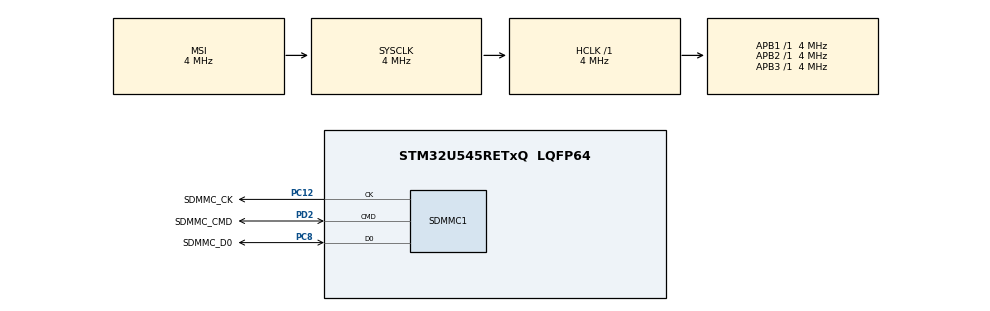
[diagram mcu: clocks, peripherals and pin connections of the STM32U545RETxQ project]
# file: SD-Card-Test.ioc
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CORTEX_M33_NS.userName=CORTEX_M33
Mcu.Family=STM32U5
Mcu.Name=STM32U545RETxQ
Mcu.Package=LQFP64
NVIC.PriorityGroup=NVIC_PRIORITYGROUP_4
PC12.GPIO_Label=SDMMC_CK
PC12.Mode=SD_1_bit
PC12.Signal=SDMMC1_CK
PC8.GPIO_Label=SDMMC_D0
PC8.GPIO_PuPd=GPIO_PULLUP
PC8.Mode=SD_1_bit
PC8.Signal=SDMMC1_D0
PD2.GPIO_Label=SDMMC_CMD
PD2.GPIO_PuPd=GPIO_PULLUP
PD2.Mode=SD_1_bit
PD2.Signal=SDMMC1_CMD
ProjectManager.HeapSize=0x200
ProjectManager.StackSize=0x400
ProjectManager.TargetToolchain=STM32CubeIDE
RCC.ADCFreq_Value=16000000
RCC.AHBFreq_Value=4000000
RCC.APB1Freq_Value=4000000
RCC.APB1TimFreq_Value=4000000
RCC.APB2Freq_Value=4000000
RCC.APB2TimFreq_Value=4000000
RCC.APB3Freq_Value=4000000
RCC.CortexFreq_Value=4000000
RCC.DACCLockSelectionVirtual=RCC_DAC1CLKSOURCE_LSI
RCC.DACCLockSelectionVirtualString=RCC_DAC1CLKSOURCE_LSI
RCC.EPOD_VALUE=4000000
RCC.HCLKFreq_Value=4000000
RCC.HSE_VALUE=16000000
RCC.HSI48_VALUE=48000000
RCC.HSI_VALUE=16000000
RCC.LSE_VALUE=32768
RCC.LSIDIV_VALUE=32000
RCC.MSI_VALUE=4000000
RCC.PLL2FRACN=0
RCC.PLL3FRACN=0
RCC.PLLFRACN=0
RCC.PWR_Regulator_Voltage_Scale=PWR_REGULATOR_VOLTAGE_SCALE3
RCC.SDMMCClockSelection=RCC_SDMMCCLKSOURCE_CLK48
RCC.SYSCLKFreq_VALUE=4000000
RCC.USBFreq_Value=48000000
RCC.VCOOutputFreq_Value=516000000
SDMMC1.ClockDiv=59
SDMMC1.HardwareFlowControl=SDMMC_HARDWARE_FLOW_CONTROL_DISABLE
VP_LPBAMQUEUE_VS_QUEUE.Mode=QUEUEMODE
VP_MEMORYMAP_VS_MEMORYMAP.Mode=CurAppReg
VP_PWR_VS_SECSignals.Mode=Security/Privilege
board=custom

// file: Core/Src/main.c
/* USER CODE BEGIN Header */
/**
  ******************************************************************************
  * @file           : main.c
  * @brief          : Main program body
  ******************************************************************************
  * @attention
  *
  * Copyright (c) 2025 STMicroelectronics.
  * All rights reserved.
  *
  * This software is licensed under terms that can be found in the LICENSE file
  * in the root directory of this software component.
  * If no LICENSE file comes with this software, it is provided AS-IS.
  *
  ******************************************************************************
  */
/* USER CODE END Header */
#include "main.h"

SD_HandleTypeDef hsd1;

/* USER CODE BEGIN PV */
char SDPath[4];
FATFS SDFatFs;
static uint8_t buffer[_MAX_SS];

/* USER CODE END PV */

void SystemClock_Config(void);
static void MX_GPIO_Init(void);
static void MX_SDMMC1_SD_Init(void);

int main(void)
{

  /* MCU Configuration--------------------------------------------------------*/

  /* Reset of all peripherals, Initializes the Flash interface and the Systick. */
  HAL_Init();

  /* USER CODE BEGIN Init */
  __HAL_RCC_PWR_CLK_ENABLE();

  /* USER CODE END Init */

  /* Configure the system clock */
  SystemClock_Config();

  /* Initialize all configured peripherals */
  MX_GPIO_Init();
  MX_SDMMC1_SD_Init();
  /* USER CODE BEGIN 2 */

  FRESULT fileResult;
  FATFS SDFatFs;

	BYTE bootSectorBuffer[512];

	DRESULT dataResult;

	UINT bytesWritten;

  // Link driver
  if (FATFS_LinkDriver(&SD_Driver, SDPath) == 0)
  {
		char label[12];
		DWORD serialNumber;
		fileResult = f_mount(&SDFatFs, SDPath, 1);
		if (fileResult != FR_OK)
		{
			Error_Handler();
		}

		FIL file;
		fileResult = f_open(&file, "0:hello69.txt", FA_WRITE | FA_CREATE_ALWAYS);
		if (fileResult != FR_OK)
		{
			Error_Handler();
		}

		const char* fileContents = "NO FUCKING WAY\n";
		fileResult = f_write(&file, fileContents, strlen(fileContents), &bytesWritten);
		if (fileResult != FR_OK || bytesWritten != strlen(fileContents))
		{
			Error_Handler();
		}

		f_close(&file);
		f_mount(NULL, "", 1);

  }

  /* USER CODE END 2 */

  /* Infinite loop */
  while (1)
  {

  }
}

void SystemClock_Config(void)
{
  RCC_OscInitTypeDef RCC_OscInitStruct = {0};
  RCC_ClkInitTypeDef RCC_ClkInitStruct = {0};

  /** Configure the main internal regulator output voltage
  */
  if (HAL_PWREx_ControlVoltageScaling(PWR_REGULATOR_VOLTAGE_SCALE3) != HAL_OK)
  {
    Error_Handler();
  }

  /** Initializes the CPU, AHB and APB buses clocks
  */
  RCC_OscInitStruct.OscillatorType = RCC_OSCILLATORTYPE_HSI48|RCC_OSCILLATORTYPE_MSI;
  RCC_OscInitStruct.HSI48State = RCC_HSI48_ON;
  RCC_OscInitStruct.MSIState = RCC_MSI_ON;
  RCC_OscInitStruct.MSICalibrationValue = RCC_MSICALIBRATION_DEFAULT;
  RCC_OscInitStruct.MSIClockRange = RCC_MSIRANGE_4;
  RCC_OscInitStruct.PLL.PLLState = RCC_PLL_NONE;
  if (HAL_RCC_OscConfig(&RCC_OscInitStruct) != HAL_OK)
  {
    Error_Handler();
  }

  /** Initializes the CPU, AHB and APB buses clocks
  */
  RCC_ClkInitStruct.ClockType = RCC_CLOCKTYPE_HCLK|RCC_CLOCKTYPE_SYSCLK
                              |RCC_CLOCKTYPE_PCLK1|RCC_CLOCKTYPE_PCLK2
                              |RCC_CLOCKTYPE_PCLK3;
  RCC_ClkInitStruct.SYSCLKSource = RCC_SYSCLKSOURCE_MSI;
  RCC_ClkInitStruct.AHBCLKDivider = RCC_SYSCLK_DIV1;
  RCC_ClkInitStruct.APB1CLKDivider = RCC_HCLK_DIV1;
  RCC_ClkInitStruct.APB2CLKDivider = RCC_HCLK_DIV1;
  RCC_ClkInitStruct.APB3CLKDivider = RCC_HCLK_DIV1;

  if (HAL_RCC_ClockConfig(&RCC_ClkInitStruct, FLASH_LATENCY_0) != HAL_OK)
  {
    Error_Handler();
  }
}

static void MX_SDMMC1_SD_Init(void)
{

  hsd1.Instance = SDMMC1;
  hsd1.Init.ClockEdge = SDMMC_CLOCK_EDGE_RISING;
  hsd1.Init.ClockPowerSave = SDMMC_CLOCK_POWER_SAVE_DISABLE;
  hsd1.Init.BusWide = SDMMC_BUS_WIDE_1B;
  hsd1.Init.HardwareFlowControl = SDMMC_HARDWARE_FLOW_CONTROL_DISABLE;
  hsd1.Init.ClockDiv = 59;
  if (HAL_SD_Init(&hsd1) != HAL_OK)
  {
    Error_Handler();
  }

}

static void MX_GPIO_Init(void)
{

  /* GPIO Ports Clock Enable */
  __HAL_RCC_GPIOC_CLK_ENABLE();
  __HAL_RCC_GPIOD_CLK_ENABLE();

}

void Error_Handler(void)
{
  __disable_irq();
  while (1)
  {
  }
}
